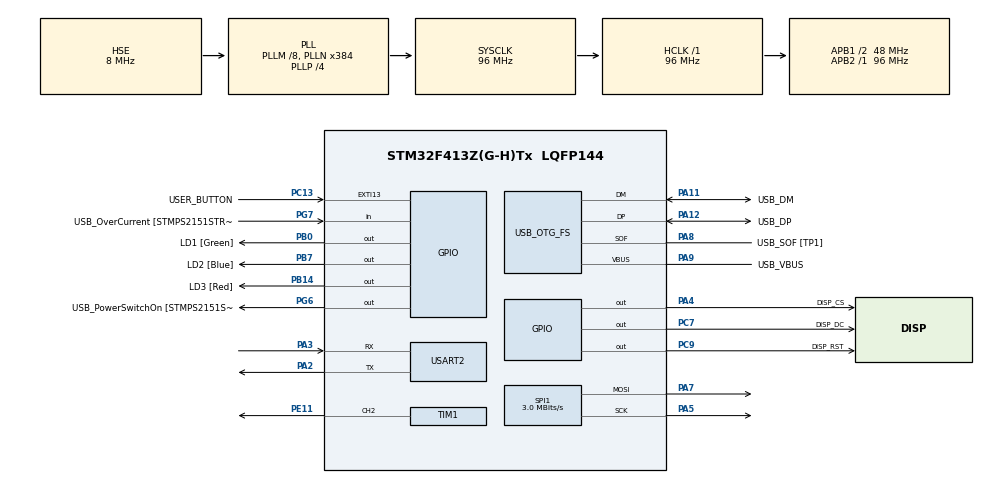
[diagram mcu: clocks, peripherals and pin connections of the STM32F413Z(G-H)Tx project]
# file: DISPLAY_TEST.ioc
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Mcu.Family=STM32F4
Mcu.Name=STM32F413Z(G-H)Tx
Mcu.Package=LQFP144
NVIC.PriorityGroup=NVIC_PRIORITYGROUP_4
PA10.GPIO_Label=USB_ID
PA10.Signal=USB_OTG_FS_ID
PA11.GPIO_Label=USB_DM
PA11.Mode=Device_Only
PA11.Signal=USB_OTG_FS_DM
PA12.GPIO_Label=USB_DP
PA12.Mode=Device_Only
PA12.Signal=USB_OTG_FS_DP
PA13.GPIO_Label=TMS
PA13.Mode=Serial_Wire
PA13.Signal=SYS_JTMS-SWDIO
PA14.GPIO_Label=TCK
PA14.Mode=Serial_Wire
PA14.Signal=SYS_JTCK-SWCLK
PA2.Mode=Asynchronous
PA2.Signal=USART2_TX
PA3.Mode=Asynchronous
PA3.Signal=USART2_RX
PA4.GPIO_Label=DISP_CS
PA4.Signal=GPIO_Output
PA5.Mode=TX_Only_Simplex_Unidirect_Master
PA5.Signal=SPI1_SCK
PA7.Mode=TX_Only_Simplex_Unidirect_Master
PA7.Signal=SPI1_MOSI
PA8.GPIO_Label=USB_SOF [TP1]
PA8.Mode=Activate_SOF_FS
PA8.Signal=USB_OTG_FS_SOF
PA9.GPIO_Label=USB_VBUS
PA9.Mode=Activate_VBUS
PA9.Signal=USB_OTG_FS_VBUS
PB0.GPIO_Label=LD1 [Green]
PB0.Signal=GPIO_Output
PB14.GPIO_Label=LD3 [Red]
PB14.Signal=GPIO_Output
PB3.GPIO_Label=SWO
PB3.Signal=SYS_JTDO-SWO
PB7.GPIO_Label=LD2 [Blue]
PB7.Signal=GPIO_Output
PC13.GPIO_Label=USER_BUTTON
PC13.Signal=GPXTI13
PC14-OSC32_IN.Mode=LSE-External-Oscillator
PC14-OSC32_IN.Signal=RCC_OSC32_IN
PC15-OSC32_OUT.Mode=LSE-External-Oscillator
PC15-OSC32_OUT.Signal=RCC_OSC32_OUT
PC7.GPIO_Label=DISP_DC
PC7.Signal=GPIO_Output
PC9.GPIO_Label=DISP_RST
PC9.Signal=GPIO_Output
PD8.GPIO_Label=STLK_RX [STM32F103CBT6_PA3]
PD8.Signal=USART3_TX
PD9.GPIO_Label=STLK_TX [STM32F103CBT6_PA2]
PD9.Signal=USART3_RX
PE11.Signal=S_TIM1_CH2
PG6.GPIO_Label=USB_PowerSwitchOn [STMPS2151STR_EN]
PG6.Signal=GPIO_Output
PG7.GPIO_Label=USB_OverCurrent [STMPS2151STR_FAULT]
PG7.Signal=GPIO_Input
PH0\ -\ OSC_IN.GPIO_Label=MCO
PH0\ -\ OSC_IN.Mode=HSE-External-Clock-Source
PH0\ -\ OSC_IN.Signal=RCC_OSC_IN
PH1\ -\ OSC_OUT.Mode=HSE-External-Clock-Source
PH1\ -\ OSC_OUT.Signal=RCC_OSC_OUT
ProjectManager.HeapSize=0x200
ProjectManager.StackSize=0x400
ProjectManager.TargetToolchain=STM32CubeIDE
RCC.48MHZClocksFreq_Value=24000000
RCC.AHBFreq_Value=96000000
RCC.APB1CLKDivider=RCC_HCLK_DIV2
RCC.APB1Freq_Value=48000000
RCC.APB1TimFreq_Value=96000000
RCC.APB2Freq_Value=96000000
RCC.APB2TimFreq_Value=96000000
RCC.CortexFreq_Value=96000000
RCC.HCLKFreq_Value=96000000
RCC.HSE_VALUE=8000000
RCC.HSI_VALUE=16000000
RCC.PLLM=8
RCC.PLLMUL=RCC_PLL_MUL9
RCC.PLLN=384
RCC.PLLP=RCC_PLLP_DIV4
RCC.PLLQ=8
RCC.PRESCALERUSB=RCC_USBCLKSOURCE_PLL_DIV1_5
RCC.SYSCLKFreq_VALUE=96000000
RCC.SYSCLKSource=RCC_SYSCLKSOURCE_PLLCLK
RCC.SYSCLKSourceVirtual=RCC_SYSCLKSOURCE_PLLCLK
RCC.USBFreq_Value=48000000
RCC.VCOOutputFreq_Value=384000000
SH.S_TIM1_CH2.0=TIM1_CH2,PWM Generation2 CH2
SPI1.BaudRatePrescaler=SPI_BAUDRATEPRESCALER_32
SPI1.CalculateBaudRate=3.0 MBits/s
SPI1.Direction=SPI_DIRECTION_2LINES
SPI1.Mode=SPI_MODE_MASTER
SPI1.VirtualType=VM_MASTER
TIM1.Channel-PWM\ Generation2\ CH2=TIM_CHANNEL_2
TIM1.Period=1000
TIM1.Prescaler=10000
USART2.VirtualMode=VM_ASYNC
USB_OTG_FS.VirtualMode=Device_Only
VP_TIM1_VS_ClockSourceINT.Mode=Internal
board=NUCLEO-F413ZH

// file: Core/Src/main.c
/* USER CODE BEGIN Header */
/**
  ******************************************************************************
  * @file           : main.c
  * @brief          : Main program body
  ******************************************************************************
  * @attention
  *
  * Copyright (c) 2024 STMicroelectronics.
  * All rights reserved.
  *
  * This software is licensed under terms that can be found in the LICENSE file
  * in the root directory of this software component.
  * If no LICENSE file comes with this software, it is provided AS-IS.
  *
  ******************************************************************************
  */
/* USER CODE END Header */
#include "main.h"
#include "spi.h"
#include "tim.h"
#include "usart.h"
#include "usb_otg.h"
#include "gpio.h"

/* USER CODE BEGIN Includes */

#include "Fonts/fonts.h"
#include "GUI_DEV/GUI_Paint.h"
#include "image/image.h"
#include "example/LCD_Test.h"
/* USER CODE END Includes */

void SystemClock_Config(void);

int main(void)
{

  /* MCU Configuration--------------------------------------------------------*/

  /* Reset of all peripherals, Initializes the Flash interface and the Systick. */
  HAL_Init();

  /* Configure the system clock */
  SystemClock_Config();

  /* Initialize all configured peripherals */
  MX_GPIO_Init();
  MX_USB_OTG_FS_PCD_Init();
  MX_SPI1_Init();
  MX_TIM1_Init();
  MX_USART2_UART_Init();
  /* USER CODE BEGIN 2 */
  LCD_1in28_test();
  /* USER CODE END 2 */

  /* Infinite loop */
  while (1)
  {

  }
}

void SystemClock_Config(void)
{
  RCC_OscInitTypeDef RCC_OscInitStruct = {0};
  RCC_ClkInitTypeDef RCC_ClkInitStruct = {0};

  /** Configure the main internal regulator output voltage
  */
  __HAL_RCC_PWR_CLK_ENABLE();
  __HAL_PWR_VOLTAGESCALING_CONFIG(PWR_REGULATOR_VOLTAGE_SCALE1);

  /** Initializes the RCC Oscillators according to the specified parameters
  * in the RCC_OscInitTypeDef structure.
  */
  RCC_OscInitStruct.OscillatorType = RCC_OSCILLATORTYPE_HSE;
  RCC_OscInitStruct.HSEState = RCC_HSE_BYPASS;
  RCC_OscInitStruct.PLL.PLLState = RCC_PLL_ON;
  RCC_OscInitStruct.PLL.PLLSource = RCC_PLLSOURCE_HSE;
  RCC_OscInitStruct.PLL.PLLM = 8;
  RCC_OscInitStruct.PLL.PLLN = 384;
  RCC_OscInitStruct.PLL.PLLP = RCC_PLLP_DIV4;
  RCC_OscInitStruct.PLL.PLLQ = 8;
  RCC_OscInitStruct.PLL.PLLR = 2;
  if (HAL_RCC_OscConfig(&RCC_OscInitStruct) != HAL_OK)
  {
    Error_Handler();
  }

  /** Initializes the CPU, AHB and APB buses clocks
  */
  RCC_ClkInitStruct.ClockType = RCC_CLOCKTYPE_HCLK|RCC_CLOCKTYPE_SYSCLK
                              |RCC_CLOCKTYPE_PCLK1|RCC_CLOCKTYPE_PCLK2;
  RCC_ClkInitStruct.SYSCLKSource = RCC_SYSCLKSOURCE_PLLCLK;
  RCC_ClkInitStruct.AHBCLKDivider = RCC_SYSCLK_DIV1;
  RCC_ClkInitStruct.APB1CLKDivider = RCC_HCLK_DIV2;
  RCC_ClkInitStruct.APB2CLKDivider = RCC_HCLK_DIV1;

  if (HAL_RCC_ClockConfig(&RCC_ClkInitStruct, FLASH_LATENCY_3) != HAL_OK)
  {
    Error_Handler();
  }
}

void Error_Handler(void)
{
  __disable_irq();
  while (1)
  {
  }
}
